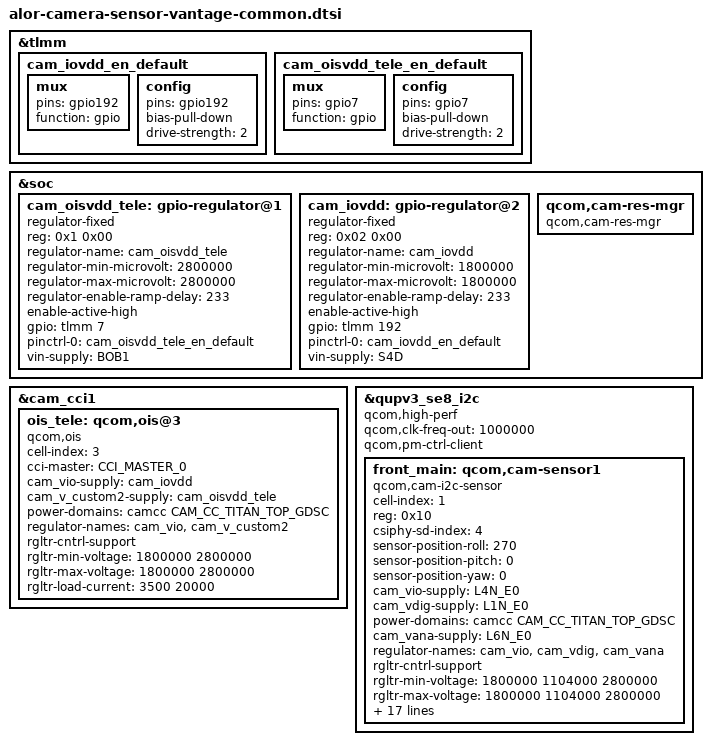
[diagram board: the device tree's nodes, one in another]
// SPDX-License-Identifier: BSD-3-Clause-Clear
/*
 * Copyright (c) Qualcomm Technologies, Inc. and/or its subsidiaries.
 * this file is based on alor-camera-sensor-mtp.dtsi
 */

#include <dt-bindings/msm-camera.h>

&tlmm {
	cam_iovdd_en_default: cam_iovdd_en_default {
		mux {
			pins = "gpio192";
			function = "gpio";
		};

		config {
			pins = "gpio192";
			bias-pull-down; /* PULL DOWN */
			drive-strength = <2>; /* 2 MA */
		};
	};

	cam_oisvdd_tele_en_default: cam_oisvdd_tele_en_default {
		mux {
			pins = "gpio7";
			function = "gpio";
		};

		config {
			pins = "gpio7";
			bias-pull-down; /* PULL DOWN */
			drive-strength = <2>; /* 2 MA */
		};
	};
};

&soc {
	cam_oisvdd_tele: gpio-regulator@1 {
		compatible = "regulator-fixed";
		reg = <0x1 0x00>;
		regulator-name = "cam_oisvdd_tele";
		regulator-min-microvolt = <2800000>;
		regulator-max-microvolt = <2800000>;
		regulator-enable-ramp-delay = <233>;
		enable-active-high;
		gpio = <&tlmm 7 0>;
		pinctrl-names = "default";
		pinctrl-0 = <&cam_oisvdd_tele_en_default>;
		vin-supply = <&BOB1>;
	};

	cam_iovdd: gpio-regulator@2 {
		compatible = "regulator-fixed";
		reg = <0x02 0x00>;
		regulator-name = "cam_iovdd";
		regulator-min-microvolt = <1800000>;
		regulator-max-microvolt = <1800000>;
		regulator-enable-ramp-delay = <233>;
		enable-active-high;
		gpio = <&tlmm 192 0>;
		pinctrl-names = "default";
		pinctrl-0 = <&cam_iovdd_en_default>;
		vin-supply = <&S4D>;
	};

	qcom,cam-res-mgr {
		compatible = "qcom,cam-res-mgr";
		status = "ok";
	};
};

&cam_cci1 {
	ois_tele: qcom,ois@3 {
		cell-index = <3>;
		compatible = "qcom,ois";
		cci-master = <CCI_MASTER_0>;
		cam_vio-supply = <&cam_iovdd>;
		cam_v_custom2-supply  = <&cam_oisvdd_tele>;
		power-domains = <&camcc CAM_CC_TITAN_TOP_GDSC>;
		regulator-names = "cam_vio", "cam_v_custom2";
		rgltr-cntrl-support;
		rgltr-min-voltage = <1800000 2800000>;
		rgltr-max-voltage = <1800000 2800000>;
		rgltr-load-current = <3500 20000>;
		status = "ok";
	};
};

&qupv3_se8_i2c{
	status = "ok";
	qcom,high-perf;
	qcom,clk-freq-out = <1000000>;
	qcom,pm-ctrl-client;

	front_main: qcom,cam-sensor1 {
		cell-index = <1>;
		reg = <0x10>;
		compatible = "qcom,cam-i2c-sensor";
		csiphy-sd-index = <4>;
		sensor-position-roll = <270>;
		sensor-position-pitch = <0>;
		sensor-position-yaw = <0>;
		cam_vio-supply = <&L4N_E0>;
		cam_vdig-supply = <&L1N_E0>;
		power-domains = <&camcc CAM_CC_TITAN_TOP_GDSC>;
		cam_vana-supply = <&L6N_E0>;
		regulator-names = "cam_vio", "cam_vdig", "cam_vana";
		rgltr-cntrl-support;
		rgltr-min-voltage = <1800000 1104000 2800000>;
		rgltr-max-voltage = <1800000 1104000 2800000>;
		rgltr-load-current = <3560 283910 50360>;
		gpio-no-mux = <0>;
		pinctrl-names = "cam_default", "cam_suspend";
		pinctrl-0 = <&cam_sensor_mclk4_active &cam_sensor_active_rst4>;
		pinctrl-1 = <&cam_sensor_mclk4_suspend &cam_sensor_suspend_rst4>;
		gpios = <&tlmm 93 0>,<&tlmm 3 0>,<&tlmm 76 0>;
		gpio-reset = <1>;
		gpio-standby = <2>;
		gpio-req-tbl-num = <0 1 2>;
		gpio-req-tbl-flags = <1 0 0>;
		gpio-req-tbl-label = "CAMIF_MCLK4","CAM_RESET4","CAM_STANDBY";
		clocks = <&cambistmclkcc CAM_BIST_MCLK_CC_MCLK4_CLK>;
		clock-names = "cam_clk";
		clock-cntl-level = "nominal";
		clock-rates = <19200000>;
		status = "ok";
	};
};
